# STM32H7A3x register map
File version: 2.0
CPU: CM7 r0p1, little endian, MPU, FPU, 4 interrupt priority bits
Registers are 32-bit, read-write, reset 0x0 unless marked. A register's access mark holds for its fields unless they carry their own. Offsets are from the block's base; [hi:lo] are bit positions; {n}, {i} and the like mark numbered series; 'fields as' and 'values as' point back to an identical list.

## FPU — Floting point unit
Base 0xE000EF34
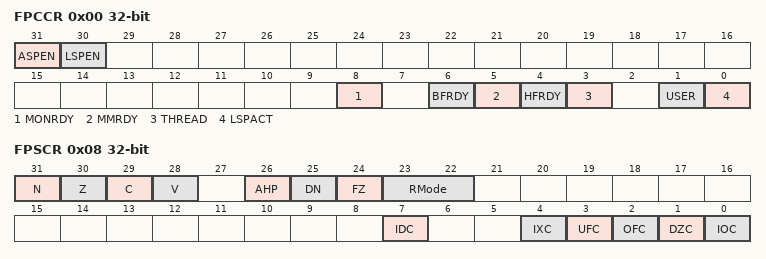
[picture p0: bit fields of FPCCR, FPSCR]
0x00 FPCCR — Floating-point context control register
  [31] ASPEN, [30] LSPEN, [8] MONRDY, [6] BFRDY, [5] MMRDY, [4] HFRDY, [3] THREAD, [1] USER, [0] LSPACT
0x04 FPCAR — Floating-point context address register
  [31:3] ADDRESS — Location of unpopulated floating-point
0x08 FPSCR — Floating-point status control register
  [31] N — Negative condition code flag
  [30] Z — Zero condition code flag
  [29] C — Carry condition code flag
  [28] V — Overflow condition code flag
  [26] AHP — Alternative half-precision control bit
  [25] DN — Default NaN mode control bit
  [24] FZ — Flush-to-zero mode control bit:
  [23:22] RMode — Rounding Mode control field
  [7] IDC — Input denormal cumulative exception bit.
  [4] IXC — Inexact cumulative exception bit
  [3] UFC — Underflow cumulative exception bit
  [2] OFC — Overflow cumulative exception bit
  [1] DZC — Division by zero cumulative exception bit.
  [0] IOC — Invalid operation cumulative exception bit

## FPU_CPACR — Floating point unit CPACR
Base 0xE000ED88
0x00 CPACR — Coprocessor access control register
  [23:20] CP

## HRTIM_Master — High Resolution Timer: Master Timers
Base 0x40017400
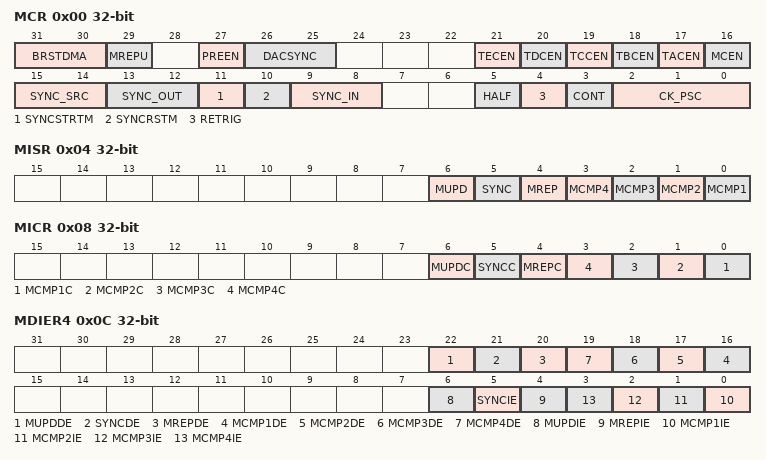
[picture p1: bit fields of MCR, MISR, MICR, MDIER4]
0x00 MCR — Master Timer Control Register
  [31:30] BRSTDMA — Burst DMA Update
  [29] MREPU — Master Timer Repetition update
  [27] PREEN — Preload enable
  [26:25] DACSYNC — AC Synchronization
  [21] TECEN — Timer E counter enable
  [20] TDCEN — Timer D counter enable
  [19] TCCEN — Timer C counter enable
  [18] TBCEN — Timer B counter enable
  [17] TACEN — Timer A counter enable
  [16] MCEN — Master Counter enable
  [15:14] SYNC_SRC — Synchronization source
  [13:12] SYNC_OUT — Synchronization output
  [11] SYNCSTRTM — Synchronization Starts Master
  [10] SYNCRSTM — Synchronization Resets Master
  [9:8] SYNC_IN — ynchronization input
  [5] HALF — Half mode enable
  [4] RETRIG — Master Re-triggerable mode
  [3] CONT — Master Continuous mode
  [2:0] CK_PSC — HRTIM Master Clock prescaler
0x04 MISR ro — Master Timer Interrupt Status Register
  [6] MUPD — Master Update Interrupt Flag
  [5] SYNC — Sync Input Interrupt Flag
  [4] MREP — Master Repetition Interrupt Flag
  [n-1] MCMP{n} (n=1..4) — Master Compare {n} Interrupt Flag
0x08 MICR wo — Master Timer Interrupt Clear Register
  [6] MUPDC — Master update Interrupt flag clear
  [5] SYNCC — Sync Input Interrupt flag clear
  [4] MREPC — Repetition Interrupt flag clear
  [n-1] MCMP{n}C (n=1..4) — Master Compare {n} Interrupt flag clear
0x0C MDIER4
  [22] MUPDDE, [21] SYNCDE, [20] MREPDE, [n+15] MCMP{n}DE (n=1..4), [6] MUPDIE, [5] SYNCIE, [4] MREPIE, [n-1] MCMP{n}IE (n=1..4)
0x10 MCNTR — Master Timer Counter Register
  [15:0] MCNT — Counter value
0x14 MPER reset 0xFFFF — Master Timer Period Register
  [15:0] MPER — Master Timer Period value
0x18 MREP — Master Timer Repetition Register
  [7:0] MREP — Master Timer Repetition counter value
0x1C MCMP1R — Master Timer Compare 1 Register
  [15:0] MCMP1 — Master Timer Compare 1 value
{0x1C+4i} MCMP{i}R (i=2..4) — Master Timer Compare {i} Register
  [15:0] MCMP{i} — Master Timer Compare {i} value

## HSEM
Base 0x48020800
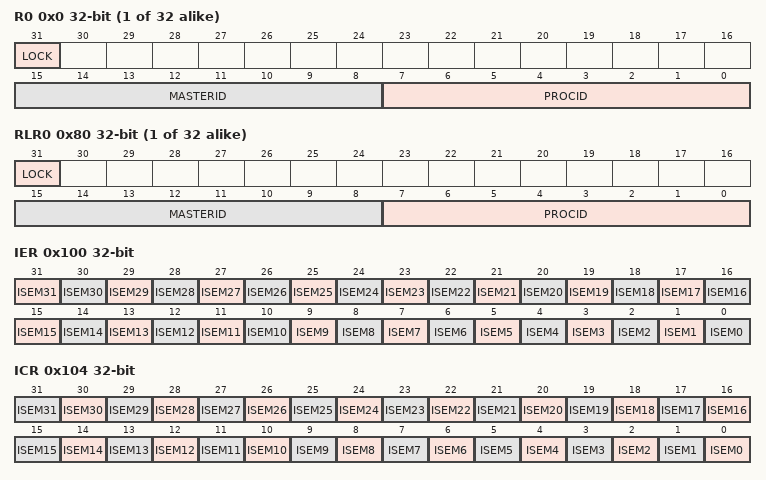
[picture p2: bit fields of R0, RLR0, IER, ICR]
{0x0+4i} R{i} (i=0..31) — HSEM register HSEM_R0 HSEM_R31
  [31] LOCK — Lock indication
  [15:8] MASTERID — Semaphore MasterID
  [7:0] PROCID — Semaphore ProcessID
{0x80+4i} RLR{i} ro (i=0..31) — HSEM Read lock register
  fields as R0
0x100 IER — HSEM Interrupt enable register
  [31] ISEM31 — Interrupt(N) semaphore n enable bit.
  [n] ISEM{n} (n=0..30) — Interrupt semaphore n enable bit
0x104 ICR ro — HSEM Interrupt clear register
  [n] ISEM{n} (n=0..31) — Interrupt(N) semaphore n clear bit
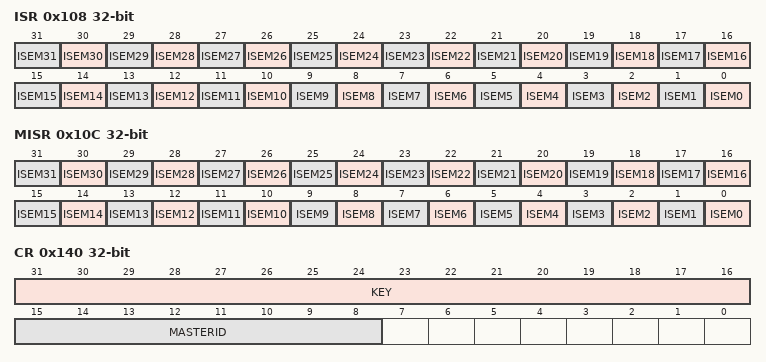
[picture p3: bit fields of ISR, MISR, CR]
0x108 ISR ro — HSEM Interrupt status register
  [n] ISEM{n} (n=0..31) — Interrupt(N) semaphore n status bit before enable (mask)
0x10C MISR ro — HSEM Masked interrupt status register
  [n] ISEM{n} (n=0..31) — masked interrupt(N) semaphore n status bit after enable (mask)
0x140 CR — HSEM Clear register
  [31:16] KEY — Semaphore clear Key
  [15:8] MASTERID — MasterID of semaphores to be cleared
0x144 KEYR — HSEM Interrupt clear register
  [31:16] KEY — Semaphore Clear Key
